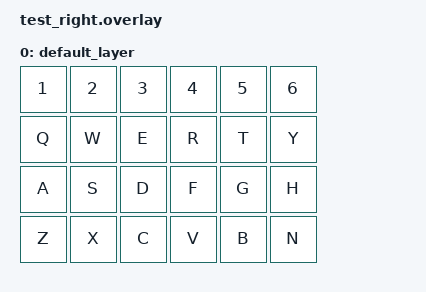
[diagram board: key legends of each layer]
/ {
    chosen {
        zmk,kscan = &kscan0;
    };

    kscan0: kscan {
        compatible = "zmk,kscan-gpio-matrix";
        wakeup-source;
        diode-direction = "col2row";

        col-gpios
            = <&xiao_d 0 GPIO_ACTIVE_HIGH>   /* col 0 — extra pinky */
            , <&xiao_d 1 GPIO_ACTIVE_HIGH>   /* col 1 — pinky       */
            , <&xiao_d 2 GPIO_ACTIVE_HIGH>   /* col 2 — ring        */
            , <&xiao_d 3 GPIO_ACTIVE_HIGH>   /* col 3 — middle      */
            , <&xiao_d 4 GPIO_ACTIVE_HIGH>   /* col 4 — index       */
            , <&xiao_d 5 GPIO_ACTIVE_HIGH>   /* col 5 — inner       */
            ;

        row-gpios
            = <&xiao_d 9 (GPIO_ACTIVE_HIGH | GPIO_PULL_DOWN)>  /* row 0 — upper  */
            , <&xiao_d 8 (GPIO_ACTIVE_HIGH | GPIO_PULL_DOWN)>  /* row 1 — top    */
            , <&xiao_d 7 (GPIO_ACTIVE_HIGH | GPIO_PULL_DOWN)>  /* row 2 — home   */
            , <&xiao_d 6 (GPIO_ACTIVE_HIGH | GPIO_PULL_DOWN)>  /* row 3 — bottom */
            , <&xiao_d 5 (GPIO_ACTIVE_HIGH | GPIO_PULL_DOWN)>  /* row 4 — thumbs */
            ;
    };

    keymap {
        compatible = "zmk,keymap";
        default_layer {
            bindings = 
    /* upper row */
    &kp N1    &kp N2    &kp N3    &kp N4    &kp N5    &kp N6
    /* top row */
    &kp Q     &kp W     &kp E     &kp R     &kp T     &kp Y
    /* home row */
    &kp A     &kp S     &kp D     &kp F     &kp G     &kp H
    /* bottom row */
    &kp Z     &kp X     &kp C     &kp V     &kp B     &kp N
            >;
        };
    };
};
